# HDSC_HC32F472 register map
Vendor: HDSC; Series: ARMCM4; File version: 1.0
CPU: CM4 r0p1, little endian, MPU, FPU, 4 interrupt priority bits
Registers are 32-bit, read-write, reset 0x0 unless marked. A register's access mark holds for its fields unless they carry their own. Offsets are from the block's base; [hi:lo] are bit positions; {n}, {i} and the like mark numbered series.

## HASH
Base 0x40008400
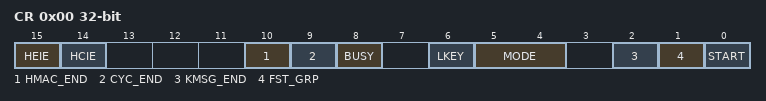
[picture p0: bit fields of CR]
0x00 CR
  [15] HEIE, [14] HCIE, [10] HMAC_END, [9] CYC_END, [8] BUSY, [6] LKEY, [5:4] MODE, [2] KMSG_END, [1] FST_GRP, [0] START
0x10 HR7
0x14 HR6
0x18 HR5
0x1C HR4
0x20 HR3
0x24 HR2
0x28 HR1
0x2C HR0
0x40 DR15
0x44 DR14
0x48 DR13
0x4C DR12
0x50 DR11
0x54 DR10
0x58 DR9
0x5C DR8
0x60 DR7
0x64 DR6
0x68 DR5
0x6C DR4
0x70 DR3
0x74 DR2
0x78 DR1
0x7C DR0

## I2C1 — desc I2C
Base 0x4004E000
Same registers: I2C2 0x4004E400, I2C3 0x4004E800
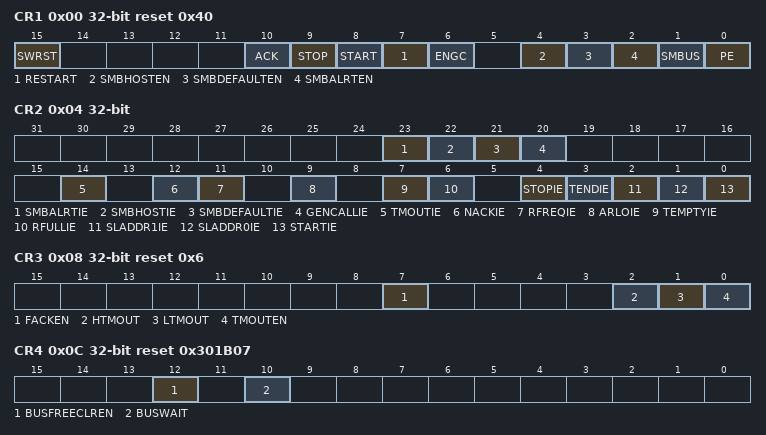
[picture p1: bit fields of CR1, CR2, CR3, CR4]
0x00 CR1 reset 0x40
  [15] SWRST, [10] ACK, [9] STOP, [8] START, [7] RESTART, [6] ENGC, [4] SMBHOSTEN, [3] SMBDEFAULTEN, [2] SMBALRTEN, [1] SMBUS, [0] PE
0x04 CR2 (reset mask 0xF052DF)
  [23] SMBALRTIE, [22] SMBHOSTIE, [21] SMBDEFAULTIE, [20] GENCALLIE, [14] TMOUTIE, [12] NACKIE, [11] RFREQIE, [9] ARLOIE, [7] TEMPTYIE, [6] RFULLIE, [4] STOPIE, [3] TENDIE, [2] SLADDR1IE, [1] SLADDR0IE, [0] STARTIE
0x08 CR3 reset 0x6
  [7] FACKEN, [2] HTMOUT, [1] LTMOUT, [0] TMOUTEN
0x0C CR4 reset 0x301B07
  [12] BUSFREECLREN, [10] BUSWAIT
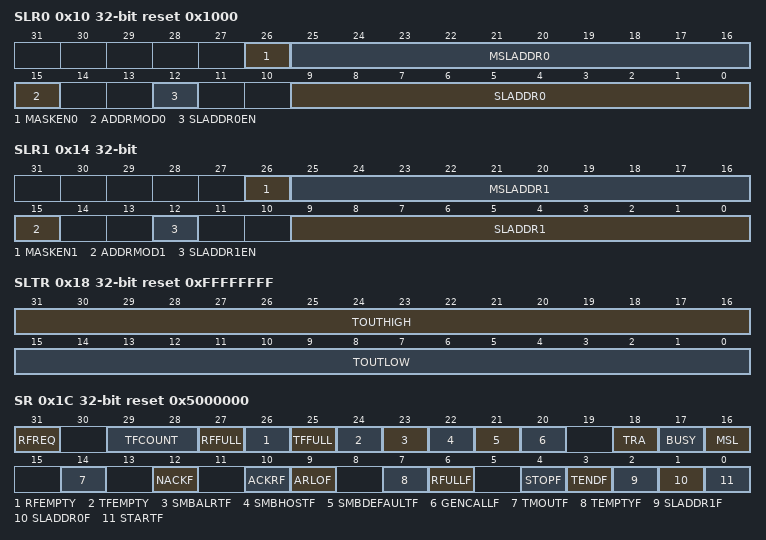
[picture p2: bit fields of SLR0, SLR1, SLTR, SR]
0x10 SLR0 reset 0x1000
  [26] MASKEN0, [25:16] MSLADDR0, [15] ADDRMOD0, [12] SLADDR0EN, [9:0] SLADDR0
0x14 SLR1
  [26] MASKEN1, [25:16] MSLADDR1, [15] ADDRMOD1, [12] SLADDR1EN, [9:0] SLADDR1
0x18 SLTR reset 0xFFFFFFFF
  [31:16] TOUTHIGH, [15:0] TOUTLOW
0x1C SR reset 0x5000000
  [31] RFREQ, [29:28] TFCOUNT, [27] RFFULL, [26] RFEMPTY, [25] TFFULL, [24] TFEMPTY, [23] SMBALRTF, [22] SMBHOSTF, [21] SMBDEFAULTF, [20] GENCALLF, [18] TRA, [17] BUSY, [16] MSL, [14] TMOUTF, [12] NACKF, [10] ACKRF, [9] ARLOF, [7] TEMPTYF, [6] RFULLF, [4] STOPF, [3] TENDF, [2] SLADDR1F, [1] SLADDR0F, [0] STARTF
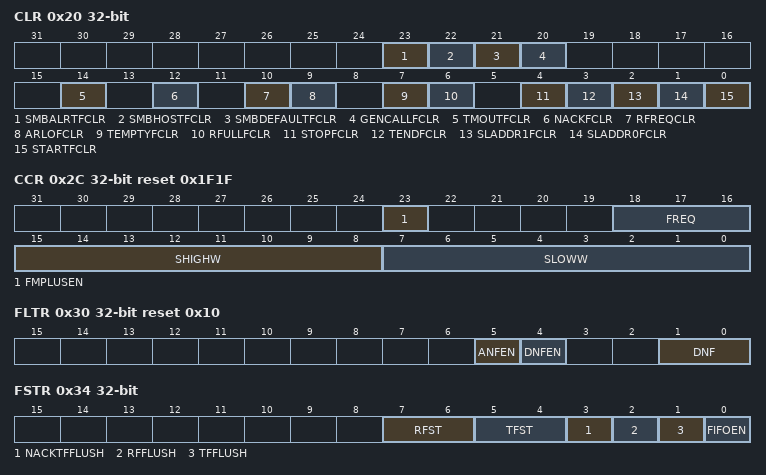
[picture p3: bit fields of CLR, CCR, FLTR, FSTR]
0x20 CLR wo
  [23] SMBALRTFCLR, [22] SMBHOSTFCLR, [21] SMBDEFAULTFCLR, [20] GENCALLFCLR, [14] TMOUTFCLR, [12] NACKFCLR, [10] RFREQCLR rw, [9] ARLOFCLR, [7] TEMPTYFCLR, [6] RFULLFCLR, [4] STOPFCLR, [3] TENDFCLR, [2] SLADDR1FCLR, [1] SLADDR0FCLR, [0] STARTFCLR
0x24 DTR 8-bit wo reset 0xFF
  [7:0] DT
0x28 DRR 8-bit ro
  [7:0] DR
0x2C CCR reset 0x1F1F
  [23] FMPLUSEN, [18:16] FREQ, [15:8] SHIGHW, [7:0] SLOWW
0x30 FLTR reset 0x10
  [5] ANFEN, [4] DNFEN, [1:0] DNF
0x34 FSTR
  [7:6] RFST, [5:4] TFST, [3] NACKTFFLUSH, [2] RFFLUSH, [1] TFFLUSH, [0] FIFOEN
0x38 SLVADDR
  [9:0] SLVADRR

## ICG
Base 0x00000400
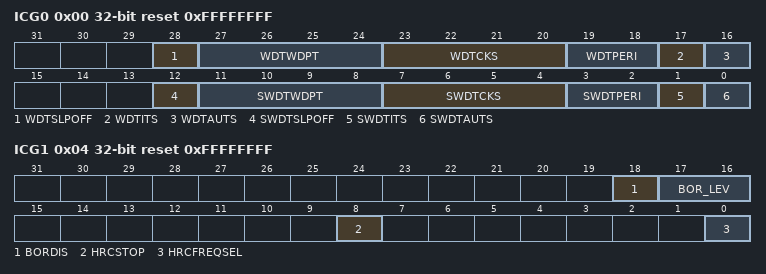
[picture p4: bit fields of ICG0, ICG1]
0x00 ICG0 ro reset 0xFFFFFFFF
  [28] WDTSLPOFF, [27:24] WDTWDPT, [23:20] WDTCKS, [19:18] WDTPERI, [17] WDTITS, [16] WDTAUTS, [12] SWDTSLPOFF, [11:8] SWDTWDPT, [7:4] SWDTCKS, [3:2] SWDTPERI, [1] SWDTITS, [0] SWDTAUTS
0x04 ICG1 ro reset 0xFFFFFFFF
  [18] BORDIS, [17:16] BOR_LEV, [8] HRCSTOP, [0] HRCFREQSEL
0x0C ICG3 ro reset 0xFFFFFFFF
  [15:0] DBUSPRT
0x10 ICG4 ro reset 0xFFFFFFFF

## INTC
Base 0x40051000
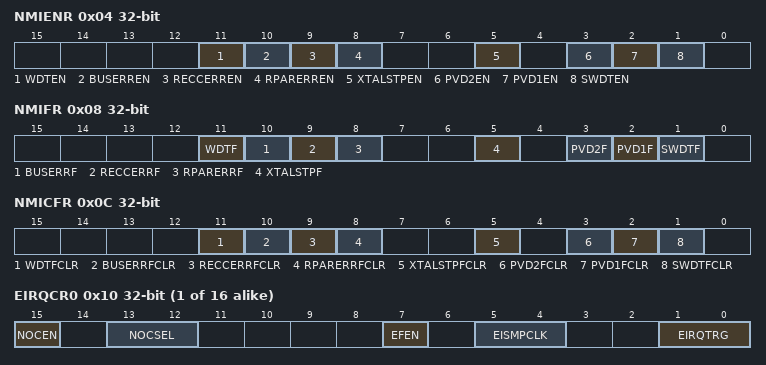
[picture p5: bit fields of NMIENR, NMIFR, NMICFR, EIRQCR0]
0x04 NMIENR
  [11] WDTEN, [10] BUSERREN, [9] RECCERREN, [8] RPARERREN, [5] XTALSTPEN, [3] PVD2EN, [2] PVD1EN, [1] SWDTEN
0x08 NMIFR
  [11] WDTF, [10] BUSERRF, [9] RECCERRF, [8] RPARERRF, [5] XTALSTPF, [3] PVD2F, [2] PVD1F, [1] SWDTF
0x0C NMICFR
  [11] WDTFCLR, [10] BUSERRFCLR, [9] RECCERRFCLR, [8] RPARERRFCLR, [5] XTALSTPFCLR, [3] PVD2FCLR, [2] PVD1FCLR, [1] SWDTFCLR
{0x10+4i} EIRQCR{i} (i=0..15)
  [15] NOCEN, [13:12] NOCSEL, [7] EFEN, [5:4] EISMPCLK, [1:0] EIRQTRG
0x50 WUPEN (reset mask 0xF7FFFFFF)
  [29] CMP4WUEN, [28] CMP3WUEN, [28] USFWUEN, [27] CMP2WUEN, [26] RXWUEN, [25] TMR2OVFWUEN, [24] TMR2GCMWUEN, [23] TMR0GCMWUEN, [22] RTCPRDWUEN, [21] RTCALMWUEN, [20] WKTMWUEN, [19] CMP1WUEN, [18] PVD2WUEN, [17] PVD1WUEN, [16] SWDTWUEN, [15:0] EIRQWUEN
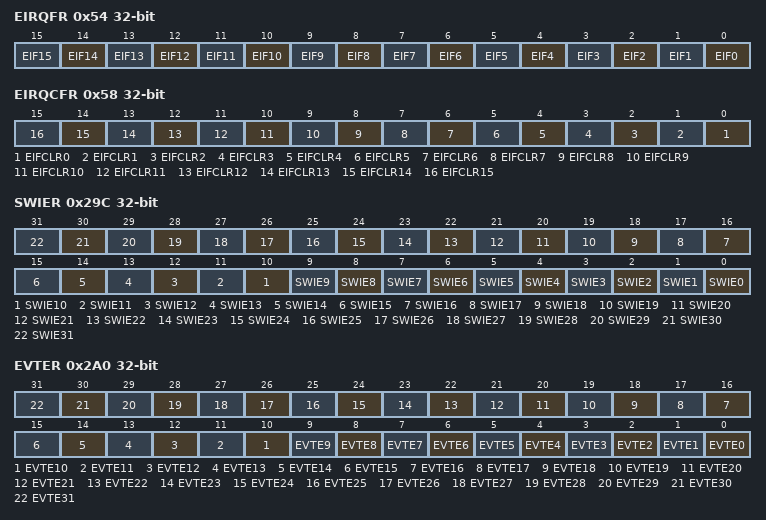
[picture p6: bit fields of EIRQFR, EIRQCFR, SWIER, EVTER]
0x54 EIRQFR
  [n] EIF{n} (n=0..15)
0x58 EIRQCFR
  [n] EIFCLR{n} (n=0..15)
{0x5C+4i} SEL{i} reset 0x1FF (i=0..15)
  [8:0] INTSEL
{0x25C+4i} MSK{i} reset 0xFFFFFFFF (i=0..15)
  [31:0] MSK
0x29C SWIER
  [n] SWIE{n} (n=0..31)
0x2A0 EVTER
  [n] EVTE{n} (n=0..31)
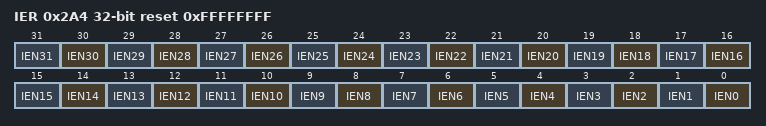
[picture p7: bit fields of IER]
0x2A4 IER reset 0xFFFFFFFF
  [n] IEN{n} (n=0..31)
